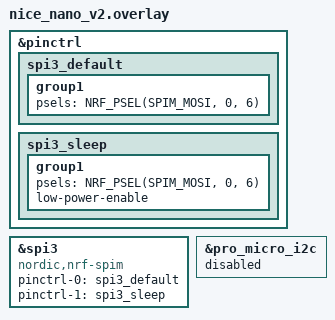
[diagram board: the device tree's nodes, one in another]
&pinctrl {
	spi3_default: spi3_default {
		group1 {
			psels = <NRF_PSEL(SPIM_MOSI, 0, 6)>;
		};
	};

	spi3_sleep: spi3_sleep {
		group1 {
			psels = <NRF_PSEL(SPIM_MOSI, 0, 6)>;
			low-power-enable;
		};
	};
};

&spi3 {
	compatible = "nordic,nrf-spim";
	status = "okay";

	pinctrl-0 = <&spi3_default>;
	pinctrl-1 = <&spi3_sleep>;
	pinctrl-names = "default", "sleep";
};

&pro_micro_i2c {
	status = "disabled";
};
